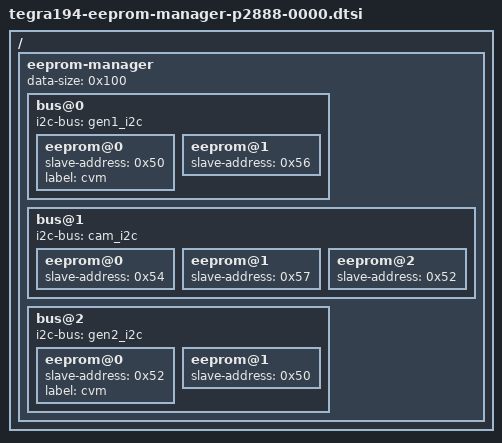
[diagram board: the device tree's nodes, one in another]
/*
 * Copyright (c) 2017-2018, NVIDIA CORPORATION.  All rights reserved.
 *
 * This program is free software; you can redistribute it and/or modify
 * it under the terms of the GNU General Public License as published by
 * the Free Software Foundation; version 2 of the License.
 *
 * This program is distributed in the hope that it will be useful, but WITHOUT
 * ANY WARRANTY; without even the implied warranty of MERCHANTABILITY or
 * FITNESS FOR A PARTICULAR PURPOSE.  See the GNU General Public License for
 * more details.
 */

/ {
	eeprom-manager {
		data-size = <0x100>;
		bus@0 {
			i2c-bus = <&gen1_i2c>;
			eeprom@0 {
				slave-address = <0x50>;
				label = "cvm";
			};
			eeprom@1 {
				slave-address = <0x56>;
			};
		};
		bus@1 {
			i2c-bus = <&cam_i2c>;
			eeprom@0 {
				slave-address = <0x54>;
			};
			eeprom@1 {
				slave-address = <0x57>;
			};
			eeprom@2 {
				slave-address = <0x52>;
			};
		};
		bus@2 {
			i2c-bus = <&gen2_i2c>;
			eeprom@0 {
				slave-address = <0x52>;
				label = "cvm";
			};
			eeprom@1 {
				slave-address = <0x50>;
			};
		};
	};
};
